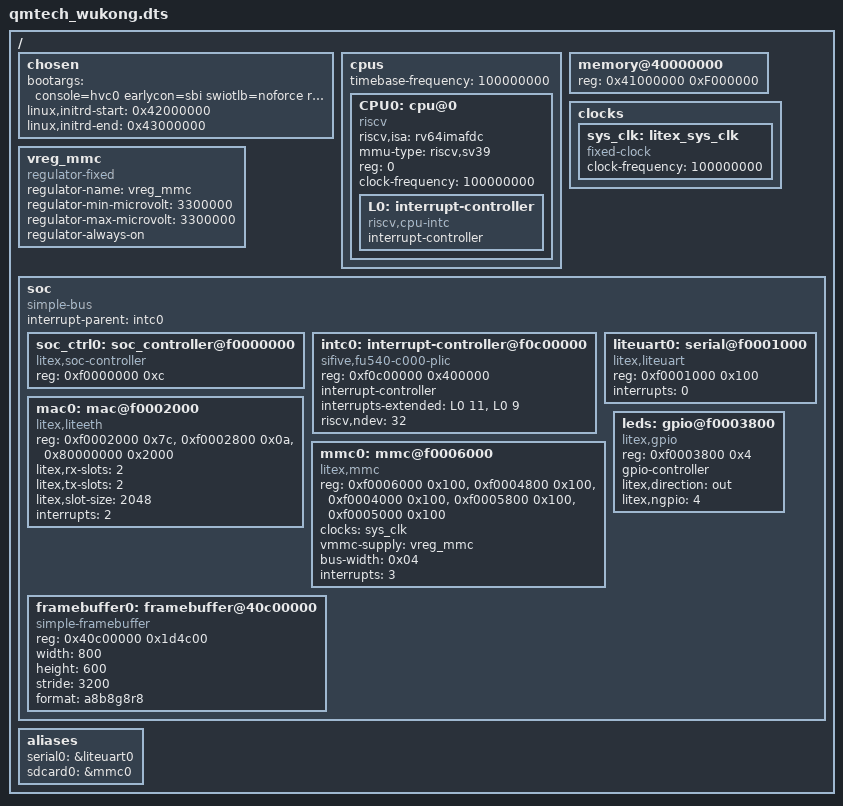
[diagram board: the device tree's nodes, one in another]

/dts-v1/;

/ {
        #address-cells = <1>;
        #size-cells    = <1>;


        chosen {
	    //bootargs = "console=liteuart earlycon=liteuart,0xf0001000  swiotlb=noforce root=/dev/ram0 rootwait"; 
	    bootargs = "console=hvc0  earlycon=sbi swiotlb=noforce root=/dev/mmcblk0p3 rw rootwait "; 
	    //bootargs = "console=hvc0  earlycon=liteuart,0xf0001000   swiotlb=noforce  "; 
	    //bootargs = "console=hvc0  earlycon=liteuart,0xf0001000  swiotlb=noforce root=/dev/mmcblk0p3 rw rootwait "; 
            linux,initrd-start = <0x42000000>;
            linux,initrd-end   = <0x43000000>;
        };

        cpus {
            #address-cells = <1>;
            #size-cells    = <0>;
            timebase-frequency = <100000000>;

            CPU0: cpu@0 {
                device_type = "cpu";
                compatible = "riscv";
                riscv,isa = "rv64imafdc";
                mmu-type = "riscv,sv39";
                reg = <0>;
                clock-frequency = <100000000>;
                status = "okay";
                
                
                L0: interrupt-controller {
                    #interrupt-cells = <0x00000001>;
                    interrupt-controller;
                    compatible = "riscv,cpu-intc";
                };
            };

            
        };

        memory@40000000 {
            device_type = "memory";
            //reg = <0x40000000 0x10000000>;
            reg = <0x41000000 0xF000000>;
        };
	/*
        reserved-memory {
            #address-cells = <1>;
            #size-cells    = <1>;
            ranges;

            opensbi@40f00000 {
                reg = <0x40f00000 0x80000>;
            };

            framebuffer@40c00000 {
                reg = <0x40c00000 0x1d4c00>;
            };

        };*/

        clocks {
            sys_clk: litex_sys_clk {
                #clock-cells = <0>;
                compatible = "fixed-clock";
                clock-frequency = <100000000>;
            };
        };

        vreg_mmc: vreg_mmc {
            compatible = "regulator-fixed";
            regulator-name = "vreg_mmc";
            regulator-min-microvolt = <3300000>;
            regulator-max-microvolt = <3300000>;
            regulator-always-on;
        };

        soc {
            #address-cells = <1>;
            #size-cells    = <1>;
            compatible = "simple-bus";
            interrupt-parent = <&intc0>;
            ranges;

            soc_ctrl0: soc_controller@f0000000 {
                compatible = "litex,soc-controller";
                reg = <0xf0000000 0xc>;
                status = "okay";
            };

            intc0: interrupt-controller@f0c00000 {
                compatible = "sifive,fu540-c000-plic", "sifive,plic-1.0.0";
                reg = <0xf0c00000 0x400000>;
                #address-cells = <0>;
                #interrupt-cells = <1>;
                interrupt-controller;
                interrupts-extended = <
                    &L0 11 &L0 9>;
                riscv,ndev = <32>;
            };

            liteuart0: serial@f0001000 {
                compatible = "litex,liteuart";
                reg = <0xf0001000 0x100>;
                interrupts = <0>;
                status = "okay";
            };

            mac0: mac@f0002000 {
                compatible = "litex,liteeth";
                reg = <0xf0002000 0x7c>,
                      <0xf0002800 0x0a>,
                      <0x80000000 0x2000>;
                reg-names = "mac", "mdio", "buffer";
                litex,rx-slots = <2>;
                litex,tx-slots = <2>;
                litex,slot-size = <2048>;
                interrupts = <2>;
                status = "okay";
            };

//            litespisdcard0: spi@f0004800 {
//                compatible = "litex,litespi";
//                reg = <0xf0004800 0x100>;
//                status = "okay";
//
//                litespi,max-bpw = <8>;
//                litespi,sck-frequency = <1500000>;
//                litespi,num-cs = <1>;
//
//                #address-cells = <1>;
//                #size-cells    = <0>;
//
//                mmc-slot@0 {
//                    compatible = "mmc-spi-slot";
//                    reg = <0>;
//                    voltage-ranges = <3300 3300>;
//                    spi-max-frequency = <1500000>;
//                    status = "okay";
//                    };
//            };
//

            mmc0: mmc@f0006000 {
                compatible = "litex,mmc";
                reg = <0xf0006000 0x100>,
                      <0xf0004800 0x100>,
                      <0xf0004000 0x100>,
                      <0xf0005800 0x100>,
                      <0xf0005000 0x100>;
                reg-names = "phy", "core", "reader", "writer", "irq";
                clocks = <&sys_clk>;
                vmmc-supply = <&vreg_mmc>;
                bus-width = <0x04>;
                interrupts = <3>;
                status = "okay";


            };

            leds: gpio@f0003800 {
                compatible = "litex,gpio";
                reg = <0xf0003800 0x4>;
                gpio-controller;
                #gpio-cells = <2>;
                litex,direction = "out";
                status = "disabled";
            };

            framebuffer0: framebuffer@40c00000 {
                compatible = "simple-framebuffer";
                reg = <0x40c00000 0x1d4c00>;
                width = <800>;
                height = <600>;
                stride = <3200>;
                format = "a8b8g8r8";
            };

        };

        aliases {

                serial0 = &liteuart0;
                //sdcard0 = &litespisdcard0;
                sdcard0 = &mmc0;

        };

};

&leds {
        litex,ngpio = <4>;
        status = "okay";
};

